# APM32F411 register map
Vendor: Geehy; File version: 2024.11.05
CPU: CM4 r1p0, little endian, 3 interrupt priority bits
Registers are 32-bit, read-write, reset 0x0 unless marked. A register's access mark holds for its fields unless they carry their own. Offsets are from the block's base; [hi:lo] are bit positions; {n}, {i} and the like mark numbered series; 'fields as' and 'values as' point back to an identical list.

## TMR2 — General purpose timers
Base 0x40000000
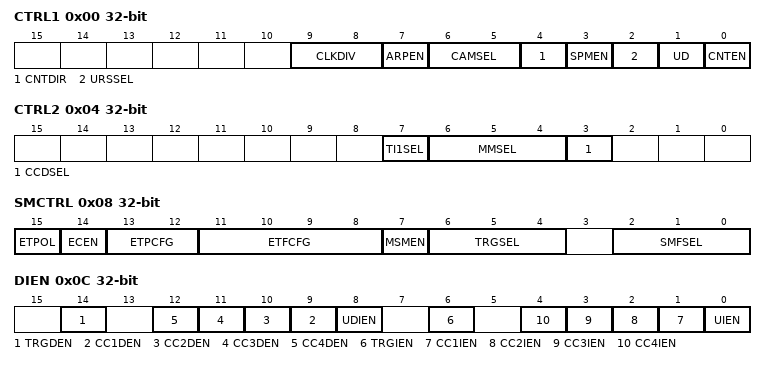
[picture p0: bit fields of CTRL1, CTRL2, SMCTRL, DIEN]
0x00 CTRL1 — control register 1
  [9:8] CLKDIV — Clock division
  [7] ARPEN — Auto-reload preload enable
  [6:5] CAMSEL — Center-aligned mode selection
  [4] CNTDIR — Direction
  [3] SPMEN — One-pulse mode
  [2] URSSEL — Update request source
  [1] UD — Update disable
  [0] CNTEN — Counter enable
0x04 CTRL2 — control register 2
  [7] TI1SEL — TI1 selection
  [6:4] MMSEL — Master mode selection
  [3] CCDSEL — Capture/compare DMA selection
0x08 SMCTRL — slave mode control register
  [15] ETPOL — External trigger polarity
  [14] ECEN — External clock enable
  [13:12] ETPCFG — External trigger prescaler
  [11:8] ETFCFG — External trigger filter
  [7] MSMEN — Master/Slave mode
  [6:4] TRGSEL — Trigger selection
  [2:0] SMFSEL — Slave mode selection
0x0C DIEN — DMA/Interrupt enable register
  [14] TRGDEN — Trigger DMA request enable
  [n+8] CC{n}DEN (n=1..4) — Capture/Compare {n} DMA request enable
  [8] UDIEN — Update DMA request enable
  [6] TRGIEN — Trigger interrupt enable
  [n] CC{n}IEN (n=1..4) — Capture/Compare {n} interrupt enable
  [0] UIEN — Update interrupt enable
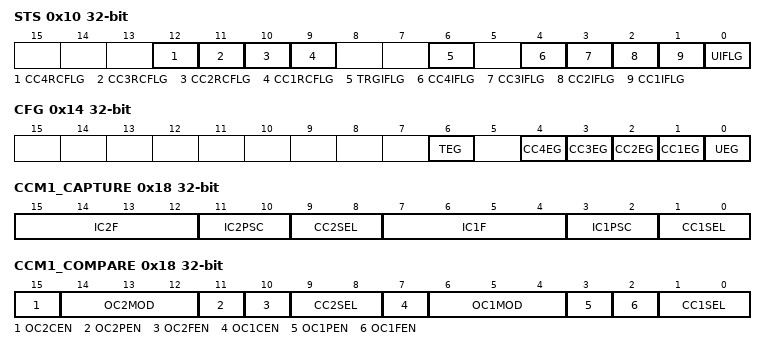
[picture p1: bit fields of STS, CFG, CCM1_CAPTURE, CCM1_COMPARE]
0x10 STS — status register
  [12] CC4RCFLG — Capture/Compare 4 overcapture flag
  [11] CC3RCFLG — Capture/Compare 3 overcapture flag
  [10] CC2RCFLG — Capture/compare 2 overcapture flag
  [9] CC1RCFLG — Capture/Compare 1 overcapture flag
  [6] TRGIFLG — Trigger interrupt flag
  [4] CC4IFLG — Capture/Compare 4 interrupt flag
  [3] CC3IFLG — Capture/Compare 3 interrupt flag
  [2] CC2IFLG — Capture/Compare 2 interrupt flag
  [1] CC1IFLG — Capture/compare 1 interrupt flag
  [0] UIFLG — Update interrupt flag
0x14 CFG wo — event generation register
  [6] TEG — Trigger generation
  [n] CC{n}EG (n=1..4) — Capture/compare {n} generation
  [0] UEG — Update generation
0x18 CCM1_CAPTURE — capture/compare mode register 1 (input mode)
  [15:12] IC2F — Input capture 2 filter
  [11:10] IC2PSC — Input capture 2 prescaler
  [9:8] CC2SEL — Capture/Compare 2 selection
  [7:4] IC1F — Input capture 1 filter
  [3:2] IC1PSC — Input capture 1 prescaler
  [1:0] CC1SEL — Capture/Compare 1 selection
0x18 CCM1_COMPARE — capture/compare mode register 1 (output mode)
  [15] OC2CEN — Output Compare 2 clear enable
  [14:12] OC2MOD — Output Compare 2 mode
  [11] OC2PEN — Output Compare 2 preload enable
  [10] OC2FEN — Output Compare 2 fast enable
  [9:8] CC2SEL — Capture/Compare 2 selection
  [7] OC1CEN — Output Compare 1 clear enable
  [6:4] OC1MOD — Output Compare 1 mode
  [3] OC1PEN — Output Compare 1 preload enable
  [2] OC1FEN — Output Compare 1 fast enable
  [1:0] CC1SEL — Capture/Compare 1 selection
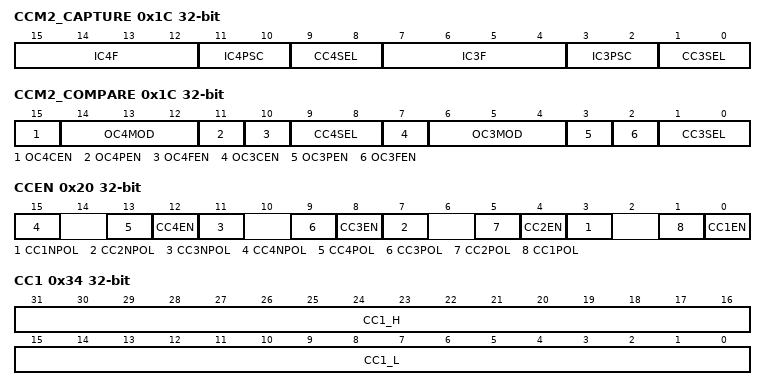
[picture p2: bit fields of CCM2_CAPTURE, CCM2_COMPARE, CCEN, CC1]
0x1C CCM2_CAPTURE — capture/compare mode register 2 (input mode)
  [15:12] IC4F — Input capture 4 filter
  [11:10] IC4PSC — Input capture 4 prescaler
  [9:8] CC4SEL — Capture/Compare 4 selection
  [7:4] IC3F — Input capture 3 filter
  [3:2] IC3PSC — Input capture 3 prescaler
  [1:0] CC3SEL — Capture/compare 3 selection
0x1C CCM2_COMPARE — capture/compare mode register 2 (output mode)
  [15] OC4CEN — Output compare 4 clear enable
  [14:12] OC4MOD — Output compare 4 mode
  [11] OC4PEN — Output compare 4 preload enable
  [10] OC4FEN — Output compare 4 fast enable
  [9:8] CC4SEL — Capture/Compare 4 selection
  [7] OC3CEN — Output compare 3 clear enable
  [6:4] OC3MOD — Output compare 3 mode
  [3] OC3PEN — Output compare 3 preload enable
  [2] OC3FEN — Output compare 3 fast enable
  [1:0] CC3SEL — Capture/Compare 3 selection
0x20 CCEN — capture/compare enable register
  [4n-1] CC{n}NPOL (n=1..4) — Capture/Compare {n} output Polarity
  [13] CC4POL — Capture/Compare 3 output Polarity
  [4n-4] CC{n}EN (n=1..4) — Capture/Compare {n} output enable
  [9] CC3POL — Capture/Compare 3 output Polarity
  [5] CC2POL — Capture/Compare 2 output Polarity
  [1] CC1POL — Capture/Compare 1 output Polarity
0x24 CNT — counter
  [31:0] CNT — Counter Value
0x28 PSC — prescaler
  [15:0] PSC — Prescaler value
0x2C AUTORLD reset 0xFFFFFFFF — auto-reload register
  [31:0] AUTORLD — Auto Reload Value
0x34 CC1 — capture/compare register 1
  [31:16] CC1_H — High Capture/Compare 1 value
  [15:0] CC1_L — Low Capture/Compare 1 value
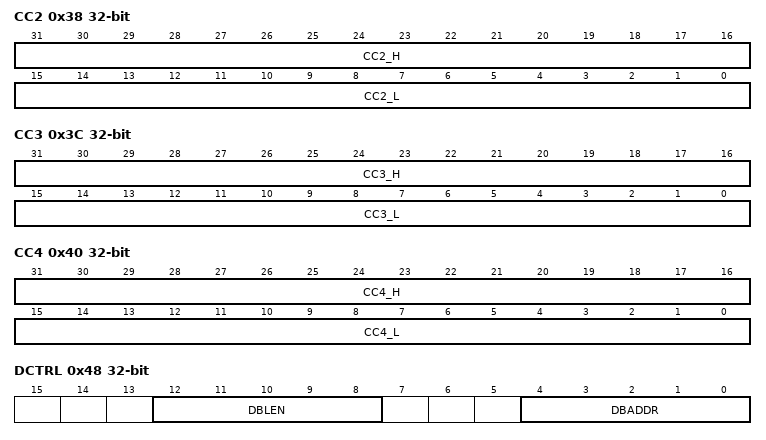
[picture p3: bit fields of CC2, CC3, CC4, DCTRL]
0x38 CC2 — capture/compare register 2
  [31:16] CC2_H — High Capture/Compare 2 value
  [15:0] CC2_L — Low Capture/Compare 2 value
0x3C CC3 — capture/compare register 3
  [31:16] CC3_H — High Capture/Compare value
  [15:0] CC3_L — Low Capture/Compare value
0x40 CC4 — capture/compare register 4
  [31:16] CC4_H — High Capture/Compare value
  [15:0] CC4_L — Low Capture/Compare value
0x48 DCTRL — DMA control register
  [12:8] DBLEN — DMA burst length
  [4:0] DBADDR — DMA base address
0x4C DMADDR — DMA address for full transfer
  [15:0] DMADDR — DMA register for burst accesses
0x50 OP — TMR2 option register
  [11:10] INTRIGRMP — Timer Input 4 remap

## TMR3 — General purpose timers
Base 0x40000400
Same registers: TMR4 0x40000800
Registers as TMR2, without OP; these are added or differ:
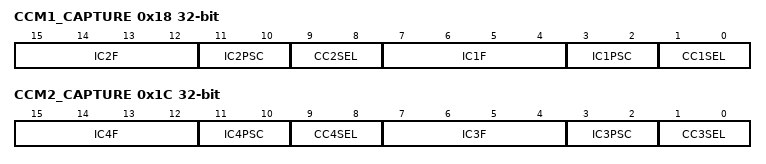
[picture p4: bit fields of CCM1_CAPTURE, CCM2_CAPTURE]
0x18 CCM1_CAPTURE (alternate view of CCM1_COMPARE) — capture/compare mode register 1 (input mode)
  fields as TMR2.CCM1_CAPTURE
0x1C CCM2_CAPTURE (alternate view of CCM2_COMPARE) — capture/compare mode register 2 (input mode)
  fields as TMR2.CCM2_CAPTURE
0x24 CNT — counter
  [15:0] CNT — Counter value
0x2C AUTORLD reset 0xFFFF — auto-reload register
  [15:0] AUTORLD — Auto-reload value
0x34 CC1 — capture/compare register 1
  [15:0] CC1_L — Low Capture/Compare 1 value
0x38 CC2 — capture/compare register 2
  [15:0] CC2_L — Low Capture/Compare 2 value
0x3C CC3 — capture/compare register 3
  [15:0] CC3_L — Low Capture/Compare value
0x40 CC4 — capture/compare register 4
  [15:0] CC4_L — Low Capture/Compare value

## TMR5 — General-purpose-timers
Base 0x40000C00
Registers as TMR2; these are added or differ:
0x24 CNT — counter
  [31:0] CNT — Counter value
0x2C AUTORLD reset 0xFFFFFFFF — auto-reload register
  [31:0] AUTORLD — Auto-reload value
0x50 OP — TMR5 option register
  [7:6] INTRIGRMP — Timer Input 4 remap
